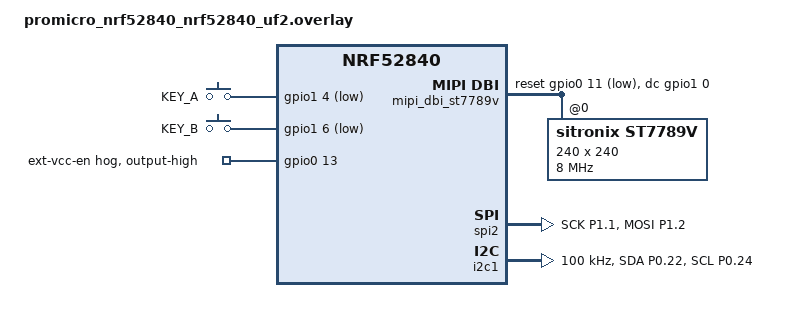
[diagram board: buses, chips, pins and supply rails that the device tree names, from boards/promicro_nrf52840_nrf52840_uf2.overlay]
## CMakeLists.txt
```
cmake_minimum_required(VERSION 3.20.0)
find_package(Zephyr REQUIRED HINTS $ENV{ZEPHYR_BASE})
project(SenseMind_Hardware VERSION 0.7.0 LANGUAGES C)
target_sources(app PRIVATE src/main.c src/sensors.c src/wire.c src/display_ui.c src/buttons.c)
```

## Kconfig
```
mainmenu "SenseMind nRF52840"
source "Kconfig.zephyr"
config SENSEMIND_TEST_DATA
    bool "Generate explicitly marked test samples instead of reading physical sensors"
    default n

config SENSEMIND_BRINGUP_LOG
    bool "Print sensor bring-up diagnostics to the USB console"
    default n

config SENSEMIND_BOOTLOADER_CMD
    bool "Allow the USB console command 'boot' to reboot into the UF2 bootloader"
    default n
```

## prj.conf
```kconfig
# M3 bring-up: BLE peripheral plus the MPU6050 I2C bus. No persistent storage.
CONFIG_BT=y
CONFIG_BT_PERIPHERAL=y
CONFIG_BT_MAX_CONN=1
CONFIG_BT_DEVICE_NAME="SenseMind-Band"
CONFIG_BT_SMP=n
CONFIG_BT_PRIVACY=n
CONFIG_BT_SETTINGS=n
CONFIG_BT_DIS=y
CONFIG_BT_DIS_MODEL_NUMBER=y
CONFIG_BT_DIS_MODEL_NUMBER_STR="SenseMind Band M2"
CONFIG_BT_DIS_MANUF_NAME=y
CONFIG_BT_DIS_MANUF_NAME_STR="SenseMind"
CONFIG_BT_DIS_FW_REV=y
CONFIG_BT_DIS_FW_REV_STR="v0.7.0"
CONFIG_BT_DIS_PNP=n

# LF source is set in the overlay for Zephyr 4.5's split clock driver.
CONFIG_CLOCK_CONTROL_NRF_K32SRC_RC_CALIBRATION=y

# This board's Zephyr definition supplies a USB CDC ACM console.
# It is an application USB stack, separate from the UF2 bootloader's CDC port.
CONFIG_SERIAL=y
CONFIG_CONSOLE=y
CONFIG_UART_CONSOLE=y
CONFIG_PRINTK=y
CONFIG_USB_DEVICE_STACK_NEXT=y
CONFIG_CDC_ACM_SERIAL_INITIALIZE_AT_BOOT=y
CONFIG_CDC_ACM_SERIAL_ENABLE_AT_BOOT=y
CONFIG_CDC_ACM_SERIAL_PRODUCT_STRING="SenseMind Band M2 Console"
CONFIG_CDC_ACM_SERIAL_MANUFACTURER_STRING="SenseMind lab test"
CONFIG_CDC_ACM_SERIAL_MAX_POWER=50

# Keep AP-protection policy consistent with the existing UICR; never lock it.
CONFIG_NRF_APPROTECT_USE_UICR=y

CONFIG_FLASH=n
CONFIG_FLASH_MAP=n
CONFIG_SETTINGS=n
CONFIG_BOOTLOADER_MCUBOOT=n
CONFIG_I2C=y
CONFIG_SPI=y
CONFIG_DISPLAY=y
CONFIG_ST7789V=y
CONFIG_ADC=n
CONFIG_PWM=n
CONFIG_GPIO=y
CONFIG_GPIO_HOGS=y
CONFIG_REBOOT=y
CONFIG_SENSEMIND_BOOTLOADER_CMD=y
CONFIG_WATCHDOG=n
CONFIG_SYSTEM_WORKQUEUE_STACK_SIZE=2048
CONFIG_BUILD_OUTPUT_HEX=y
CONFIG_BUILD_OUTPUT_BIN=y
CONFIG_BUILD_OUTPUT_UF2=y
CONFIG_MINIMAL_LIBC=y
CONFIG_MAIN_STACK_SIZE=8192
# Runtime high-water measurement for the UI thread (debug page).
CONFIG_INIT_STACKS=y
CONFIG_THREAD_STACK_INFO=y
CONFIG_BT_BUF_ACL_RX_SIZE=251
CONFIG_BT_BUF_ACL_TX_SIZE=251
CONFIG_BT_L2CAP_TX_MTU=247
CONFIG_BT_GATT_CLIENT=y
CONFIG_ENTROPY_GENERATOR=y
```

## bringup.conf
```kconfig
# Hardware bring-up build: real sensors plus periodic raw readings on the USB console.
CONFIG_SENSEMIND_TEST_DATA=n
CONFIG_SENSEMIND_BRINGUP_LOG=y
CONFIG_SENSEMIND_BOOTLOADER_CMD=y
```

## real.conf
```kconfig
CONFIG_SENSEMIND_TEST_DATA=n
```

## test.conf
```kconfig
CONFIG_SENSEMIND_TEST_DATA=y
```

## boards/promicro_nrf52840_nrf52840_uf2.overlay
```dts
#include <zephyr/dt-bindings/display/panel.h>
#include <zephyr/dt-bindings/gpio/gpio.h>

/* Adafruit nRF52 UF2 bootloader 0.6.0 accepts app writes below 0xAD000. */
&code_partition {
	reg = <0x00026000 0x00087000>;
};

/* The M2 application has no persistent flash storage. */
/delete-node/ &storage_partition;

/* Do not request any NFC or reset-pin UICR changes at startup. */
&uicr {
	/delete-property/ nfct-pins-as-gpios;
	/delete-property/ gpio-as-nreset;
};

&lfclk {
	k32src = "rc";
	k32src-accuracy-ppm = <500>;
};

/* Radio, native USB, sensor I2C and the ST7789 SPI bus are needed. */
&uart0 { status = "disabled"; };
&adc { status = "disabled"; };
&pwm0 { status = "disabled"; };
&ieee802154 { status = "disabled"; };

/* GPIO1 is used for the display DC/CS lines (P1.00/P1.07). */
&gpio1 { status = "okay"; };

/ {
	leds { status = "disabled"; };
	pwmleds { status = "disabled"; };
};

/*
 * MPU6050 bus on the board's D4/D5 pins: SDA P0.22, SCL P0.24.
 * D2/D3 (P0.17/P0.20) did not respond reliably on this board.
 */
&pinctrl {
	i2c1_sens: i2c1_sens {
		group1 {
			psels = <NRF_PSEL(TWIM_SDA, 0, 22)>,
				<NRF_PSEL(TWIM_SCL, 0, 24)>;
			bias-pull-up;
		};
	};

	i2c1_sens_sleep: i2c1_sens_sleep {
		group1 {
			psels = <NRF_PSEL(TWIM_SDA, 0, 22)>,
				<NRF_PSEL(TWIM_SCL, 0, 24)>;
			low-power-enable;
		};
	};

	/* ST7789: SCK P1.01, MOSI P1.02.  The panel has no MISO. */
	spi2_st7789: spi2_st7789 {
		group1 {
			psels = <NRF_PSEL(SPIM_SCK, 1, 1)>,
				<NRF_PSEL(SPIM_MOSI, 1, 2)>;
		};
	};

	spi2_st7789_sleep: spi2_st7789_sleep {
		group1 {
			psels = <NRF_PSEL(SPIM_SCK, 1, 1)>,
				<NRF_PSEL(SPIM_MOSI, 1, 2)>;
			low-power-enable;
		};
	};
};

&spi2 {
	status = "okay";
	compatible = "nordic,nrf-spim";
	pinctrl-0 = <&spi2_st7789>;
	pinctrl-1 = <&spi2_st7789_sleep>;
	pinctrl-names = "default", "sleep";
	cs-gpios = <&gpio1 7 GPIO_ACTIVE_LOW>;
};

/ {
	chosen {
		zephyr,display = &st7789v;
	};

	buttons {
		compatible = "gpio-keys";

		button_a: button_a {
			gpios = <&gpio1 4 (GPIO_ACTIVE_LOW | GPIO_PULL_UP)>;
			label = "KEY_A";
		};

		button_b: button_b {
			gpios = <&gpio1 6 (GPIO_ACTIVE_LOW | GPIO_PULL_UP)>;
			label = "KEY_B";
		};
	};

	mipi_dbi_st7789v: mipi-dbi-spi {
		compatible = "zephyr,mipi-dbi-spi";
		spi-dev = <&spi2>;
		dc-gpios = <&gpio1 0 GPIO_ACTIVE_HIGH>;
		reset-gpios = <&gpio0 11 GPIO_ACTIVE_LOW>;
		write-only;
		#address-cells = <1>;
		#size-cells = <0>;

		st7789v: st7789v@0 {
			compatible = "sitronix,st7789v";
			reg = <0>;
			mipi-max-frequency = <8000000>;
			width = <240>;
			height = <240>;
			x-offset = <0>;
			y-offset = <0>;
			vcom = <0x19>;
			gctrl = <0x35>;
			vrhs = <0x12>;
			vdvs = <0x20>;
			mdac = <0x00>;
			gamma = <0x01>;
			pixel-format = <PANEL_PIXEL_FORMAT_RGB_565>;
			lcm = <0x2c>;
			porch-param = [0c 0c 00 33 33];
			cmd2en-param = [5a 69 02 01];
			pwctrl1-param = [a4 a1];
			pvgam-param = [d0 04 0d 11 13 2b 3f 54 4c 18 0d 0b 1f 23];
			nvgam-param = [d0 04 0c 11 13 2c 3f 44 51 2f 1f 1f 20 23];
			ram-param = [00 f0];
			rgb-param = [cd 08 14];
			mipi-mode = "MIPI_DBI_MODE_SPI_4WIRE";
		};
	};
};

&i2c0 { status = "disabled"; };

&i2c1 {
	status = "okay";
	compatible = "nordic,nrf-twi";
	clock-frequency = <100000>;
	pinctrl-0 = <&i2c1_sens>;
	pinctrl-1 = <&i2c1_sens_sleep>;
	pinctrl-names = "default", "sleep";
};

/*
 * P0.13 enables the board's 3.3V/VCC output pins (official board doc:
 * driving it low cuts power to them). Keep it high from boot.
 */
&gpio0 {
	status = "okay";
	ext_vcc_en: ext-vcc-en {
		gpio-hog;
		gpios = <13 GPIO_ACTIVE_HIGH>;
		output-high;
		line-name = "ext-vcc-en";
	};
};
```

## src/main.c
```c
/* SenseMind raw telemetry v1. Never flashes, updates UICR, estimates HR, or enables display. */
#include <errno.h>
#include <stdarg.h>
#include <stdio.h>
#include <string.h>
#include <zephyr/kernel.h>
#include <zephyr/bluetooth/bluetooth.h>
#include <zephyr/bluetooth/conn.h>
#include <zephyr/bluetooth/gatt.h>
#include <zephyr/bluetooth/uuid.h>
#include <zephyr/random/random.h>
#include <zephyr/sys/byteorder.h>
#include <zephyr/sys/printk.h>
#include <zephyr/sys/reboot.h>
#include <zephyr/drivers/uart.h>
#include <hal/nrf_ficr.h>
#include <hal/nrf_power.h>
#include "sensors.h"
#include "wire.h"
#include "display_ui.h"
BUILD_ASSERT(DT_REG_ADDR(DT_CHOSEN(zephyr_code_partition))==0x26000,"unsafe UF2 start");
BUILD_ASSERT(DT_REG_SIZE(DT_CHOSEN(zephyr_code_partition))==0x87000,"unsafe UF2 limit");
BUILD_ASSERT(!DT_PROP_OR(DT_NODELABEL(uicr),nfct_pins_as_gpios,0),"UICR NFC write prohibited");
BUILD_ASSERT(!DT_PROP_OR(DT_NODELABEL(uicr),gpio_as_nreset,0),"UICR reset write prohibited");
#define VERSION "v0.7.0"
#define MAX_JSON 4096
#define QUEUE_N 4
#define BATCH_N 64
#define UUID(v) BT_UUID_128_ENCODE(v,0x1d2a,0x4f6e,0x9a7b,0x1c2d3e4f5a60)
static struct bt_uuid_128 service_uuid=BT_UUID_INIT_128(UUID(0x5f9b3c10));
static struct bt_uuid_128 data_uuid=BT_UUID_INIT_128(UUID(0x5f9b3c11));
static struct bt_uuid_128 ack_uuid=BT_UUID_INIT_128(UUID(0x5f9b3c12));
struct message { uint32_t id;uint16_t len,crc;char json[MAX_JSON]; };
static struct message queue[QUEUE_N];static unsigned head,used;
static uint32_t next_id,overruns;static uint16_t fragment;
static int64_t retry_at;
static struct bt_conn *connection;static bool subscribed;
K_MUTEX_DEFINE(lock);
struct batch { int32_t value[6][BATCH_N];unsigned count;uint64_t first_us;int last_error;uint32_t sequence; };
static struct batch imu,ppg;
static char device_id[40],boot_id[40],json_buffer[MAX_JSON];
static void enqueue(const char *json,size_t len) {
 k_mutex_lock(&lock,K_FOREVER);
 if(used==QUEUE_N||len>=MAX_JSON) { overruns++;k_mutex_unlock(&lock);return; }
 struct message *m=&queue[(head+used)%QUEUE_N];m->id=++next_id;m->len=len;
 memcpy(m->json,json,len);m->crc=sm_crc16((const uint8_t *)json,len);used++;
 k_mutex_unlock(&lock);
}
static ssize_t read_data(struct bt_conn *c,const struct bt_gatt_attr *a,void *b,uint16_t len,uint16_t offset) {
 /* READ exposes the transport state, not an ambiguous truncated JSON packet. */
 uint8_t status[8];k_mutex_lock(&lock,K_FOREVER);sys_put_le32(used,status);sys_put_le32(overruns,status+4);k_mutex_unlock(&lock);
 return bt_gatt_attr_read(c,a,b,len,offset,status,sizeof(status));
}
static void ccc(const struct bt_gatt_attr *a,uint16_t value) { ARG_UNUSED(a);subscribed=value==BT_GATT_CCC_NOTIFY;sm_ui_set_ble(connection!=NULL,subscribed); }
static ssize_t write_ack(struct bt_conn *c,const struct bt_gatt_attr *a,const void *buf,uint16_t len,uint16_t offset,uint8_t flags) {
 ARG_UNUSED(c);ARG_UNUSED(a);ARG_UNUSED(flags);const uint8_t *p=buf;
 if(offset||len!=8||p[0]!='S'||p[1]!='A'||p[2]!=1||p[3]>1)return BT_GATT_ERR(BT_ATT_ERR_VALUE_NOT_ALLOWED);
 k_mutex_lock(&lock,K_FOREVER);
 if(used&&sys_get_le32(p+4)==queue[head].id) {
   if(p[3]==0){head=(head+1)%QUEUE_N;used--;}
   fragment=0;retry_at=0;
 }
 k_mutex_unlock(&lock);return len;
}
BT_GATT_SERVICE_DEFINE(sm_service,
 BT_GATT_PRIMARY_SERVICE(&service_uuid),
 BT_GATT_CHARACTERISTIC(&data_uuid.uuid,BT_GATT_CHRC_READ|BT_GATT_CHRC_NOTIFY,BT_GATT_PERM_READ,read_data,NULL,NULL),
 BT_GATT_CCC(ccc,BT_GATT_PERM_READ|BT_GATT_PERM_WRITE),
 BT_GATT_CHARACTERISTIC(&ack_uuid.uuid,BT_GATT_CHRC_WRITE,BT_GATT_PERM_WRITE,NULL,write_ack,NULL));
static const struct bt_data ad[]={BT_DATA_BYTES(BT_DATA_FLAGS,(BT_LE_AD_GENERAL|BT_LE_AD_NO_BREDR)),BT_DATA(BT_DATA_NAME_COMPLETE,CONFIG_BT_DEVICE_NAME,sizeof(CONFIG_BT_DEVICE_NAME)-1)};
static const struct bt_data sd[]={BT_DATA_BYTES(BT_DATA_UUID128_ALL,UUID(0x5f9b3c10))};
static void advertise(struct k_work *work);
K_WORK_DELAYABLE_DEFINE(adv_work,advertise);
static void advertise(struct k_work *work) { ARG_UNUSED(work);int rc=bt_le_adv_start(BT_LE_ADV_CONN_FAST_2,ad,ARRAY_SIZE(ad),sd,ARRAY_SIZE(sd));if(rc&&rc!=-EALREADY){printk("SM ADV retry error=%d\n",rc);k_work_reschedule(&adv_work,K_SECONDS(2));} }
static void mtu_exchanged(struct bt_conn *c,uint8_t error,struct bt_gatt_exchange_params *params) {
 ARG_UNUSED(c);ARG_UNUSED(error);ARG_UNUSED(params);
}
static struct bt_gatt_exchange_params mtu_params={.func=mtu_exchanged};
static void connected(struct bt_conn *c,uint8_t error) {
 if(error){k_work_reschedule(&adv_work,K_SECONDS(1));return;}
 k_mutex_lock(&lock,K_FOREVER);connection=bt_conn_ref(c);fragment=0;retry_at=0;k_mutex_unlock(&lock);
 sm_ui_set_ble(true,false);
 (void)bt_gatt_exchange_mtu(c,&mtu_params);
}
static void disconnected(struct bt_conn *c,uint8_t reason) {
 ARG_UNUSED(c);ARG_UNUSED(reason);k_mutex_lock(&lock,K_FOREVER);
 if(connection){bt_conn_unref(connection);connection=NULL;}subscribed=false;fragment=0;retry_at=0;k_mutex_unlock(&lock);
 sm_ui_set_ble(false,false);
 k_work_reschedule(&adv_work,K_SECONDS(1));
}
BT_CONN_CB_DEFINE(callbacks)={.connected=connected,.disconnected=disconnected};
static void transmit(void) {
 uint8_t frame[244];k_mutex_lock(&lock,K_FOREVER);
 if(!connection||!subscribed||!used){k_mutex_unlock(&lock);return;}
 struct message *m=&queue[head];uint16_t mtu=bt_gatt_get_mtu(connection);
 unsigned payload=MIN(sizeof(frame)-16,(unsigned)(mtu>19?mtu-19:0));
 if(!payload){k_mutex_unlock(&lock);return;}
 unsigned count=DIV_ROUND_UP(m->len,payload);
 if(fragment>=count) {
   if(k_uptime_get()<retry_at){k_mutex_unlock(&lock);return;}
   fragment=0;
 }
 size_t size=sm_fragment((const uint8_t *)m->json,m->len,m->crc,m->id,fragment,payload,frame,sizeof(frame));
 int rc=size?bt_gatt_notify(connection,&sm_service.attrs[2],frame,size):-EINVAL;
 if(!rc){fragment++;if(fragment==count)retry_at=k_uptime_get()+5000;}
 k_mutex_unlock(&lock);
}
static int append(char **p,size_t *left,const char *fmt,...) {
 va_list ap;va_start(ap,fmt);int n=vsnprintf(*p,*left,fmt,ap);va_end(ap);
 if(n<0||(size_t)n>=*left)return -ENOSPC;
 *p+=n;*left-=n;return 0;
}
static void packet(struct batch *b,bool optical) {
 char *p=json_buffer;size_t left=sizeof(json_buffer);bool has=b->count>0;
 const char *names[6]={"ax_raw","ay_raw","az_raw","gx_raw","gy_raw","gz_raw"};
 const char *source=IS_ENABLED(CONFIG_SENSEMIND_TEST_DATA)?"test":"hardware";
 const char *sensor=optical?"max30102":"mpu6050";const char *stream=optical?"ppg":"imu";
 int rc=append(&p,&left,"{\"protocol_version\":\"1.0\",\"device_id\":\"%s\",\"device_type\":\"wearable_nrf52840\",\"source_type\":\"%s\",\"timestamp\":null,\"boot_id\":\"%s\",\"stream_id\":\"%s\",\"sequence_number\":%u,\"sensor_type\":\"%s\",\"sampling_rate\":%s,\"measurements\":{",device_id,source,boot_id,stream,b->sequence++,sensor,has?(optical?"50":"10"):"null");
 for(unsigned ch=0;has&&ch<(optical?2:6)&&!rc;ch++) {
   rc=append(&p,&left,"%s\"%s\":{\"unit\":\"count\",\"samples\":[",ch?",":"",optical?(ch?"ir":"red"):names[ch]);
   for(unsigned i=0;i<b->count&&!rc;i++)rc=append(&p,&left,"%s%d",i?",":"",b->value[ch][i]);
   if(!rc)rc=append(&p,&left,"],\"validity\":[");
   for(unsigned i=0;i<b->count&&!rc;i++)rc=append(&p,&left,"%strue",i?",":"");
   if(!rc)rc=append(&p,&left,"]}");
 }
 bool present=has||b->last_error!=-ENODEV;
 if(!rc)rc=append(&p,&left,"},\"signal_quality\":\"%s\",\"device_status\":{\"connected\":%s,\"sampling\":%s,\"sensor_present\":%s,\"error_codes\":[%s],\"buffer_overruns\":%u,\"heartbeat_interval_seconds\":1,\"firmware_version\":\"%s\"},\"device_time_us\":%llu,\"time_sync\":{\"status\":\"unsynced\"},\"packet_kind\":\"%s\"}",has?"unknown":"invalid",connection?"true":"false",has?"true":"false",present?"true":"false",b->last_error?"\"SENSOR_READ_OR_FIFO_ERROR\"":"",overruns,VERSION,(unsigned long long)(has?b->first_us:k_uptime_get()*1000),has?"samples":"status");
 if(!rc)enqueue(json_buffer,p-json_buffer);else overruns++;
 b->count=0;
}
static void collect(struct batch *b,const int32_t *v,unsigned channels) {
 if(b->count==BATCH_N){overruns++;return;}
 if(!b->count)b->first_us=k_uptime_get()*1000;
 for(unsigned i=0;i<channels;i++){b->value[i][b->count]=v[i];}
 b->count++;
}
#if CONFIG_SENSEMIND_BOOTLOADER_CMD
static void enter_bootloader(void) {
 printk("SM reboot to UF2 bootloader\n");
 k_msleep(20);
 NRF_POWER->GPREGRET=0x57; /* DFU_MAGIC_UF2_RESET: Adafruit/nice!nano UF2 bootloader */
 sys_reboot(SYS_REBOOT_COLD);
}
static void poll_boot_command(void) {
 static char boot_cmd[8];static unsigned boot_len;
 static const struct device *console=DEVICE_DT_GET(DT_CHOSEN(zephyr_console));
 unsigned char c;
 if(!device_is_ready(console))return;
 while(uart_poll_in(console,&c)==0) {
   if(c=='\r'||c=='\n') {
     boot_cmd[boot_len]=0;
     if(!strcmp(boot_cmd,"boot")||!strcmp(boot_cmd,"dfu"))enter_bootloader();
     boot_len=0;
   } else if(boot_len<sizeof(boot_cmd)-1)boot_cmd[boot_len++]=(char)c;
 }
}
#endif
int main(void) {
 snprintf(device_id,sizeof(device_id),"band-%08x%08x",NRF_FICR->DEVICEID[0],NRF_FICR->DEVICEID[1]);
 snprintf(boot_id,sizeof(boot_id),"%08x%08x",sys_rand32_get(),sys_rand32_get());
 sm_ui_set_ids(device_id,boot_id,VERSION);
 if(IS_ENABLED(CONFIG_SENSEMIND_BRINGUP_LOG))printk("SM BOOT %s device=%s\n",VERSION,device_id);
 if(!IS_ENABLED(CONFIG_SENSEMIND_TEST_DATA)) {
   int sensor_rc=sm_sensors_init();
   if(IS_ENABLED(CONFIG_SENSEMIND_BRINGUP_LOG))printk("SM sensors init rc=%d\n",sensor_rc);
 }
 sm_ui_set_sensors(sm_imu_present(),sm_ppg_present());
 int rc=bt_enable(NULL);if(rc){printk("SM BLE unavailable %d\n",rc);return rc;}
 k_work_reschedule(&adv_work,K_NO_WAIT);
 sm_ui_set_ble(false,false);
 int64_t sensor_at=0,imu_at=0,packet_at=1000,log_at=1000,scan_at=2000;
 int32_t last_imu[6]={0};uint32_t last_red=0,last_ir=0;bool have_imu=false,have_ppg=false;
 while(1) {
   int64_t now=k_uptime_get();
   if(now>=sensor_at) {
     sensor_at=now+20;uint32_t red,ir;
     if(IS_ENABLED(CONFIG_SENSEMIND_TEST_DATA)){red=100000+(now%100);ir=120000+(now%100);rc=0;}
     else rc=sm_max30102_read(&red,&ir);
     ppg.last_error=(rc==-EAGAIN)?0:rc;
     if(!rc){
       int32_t v[2]={red,ir};collect(&ppg,v,2);sm_ui_push_ppg(red,ir);
       last_red=red;last_ir=ir;have_ppg=true;
       if(!IS_ENABLED(CONFIG_SENSEMIND_TEST_DATA)) {
         /* Drain bounded backlog so scheduler jitter cannot silently lower FIFO rate. */
         for(unsigned n=1;n<4;n++) {
           int more=sm_max30102_read(&red,&ir);
           if(more){if(more!=-EAGAIN)ppg.last_error=more;break;}
           v[0]=red;v[1]=ir;collect(&ppg,v,2);sm_ui_push_ppg(red,ir);
           last_red=red;last_ir=ir;
         }
       }
     }
     if(ppg.last_error==-EOVERFLOW){overruns++;ppg.count=0;}
   }
   if(now>=imu_at) {
     imu_at=now+100;int16_t raw[6];
     if(IS_ENABLED(CONFIG_SENSEMIND_TEST_DATA)){memset(raw,0,sizeof(raw));raw[2]=16384;rc=0;}else rc=sm_mpu6050_read(raw);
     imu.last_error=rc;
     if(!rc){int32_t v[6];for(unsigned i=0;i<6;i++){v[i]=raw[i];last_imu[i]=raw[i];}collect(&imu,v,6);sm_ui_set_imu(raw);have_imu=true;}
   }
   if(now>=packet_at){
     packet_at=now+1000;packet(&imu,false);packet(&ppg,true);
     sm_ui_set_counters(imu.sequence,overruns);
     sm_ui_set_sensors(imu.last_error==0,ppg.last_error==0);
   }
   if(IS_ENABLED(CONFIG_SENSEMIND_BRINGUP_LOG)&&now>=log_at) {
     log_at=now+1000;
     printk("SM BRINGUP imu_err=%d ppg_err=%d imu=%d ppg=%d",imu.last_error,ppg.last_error,have_imu,have_ppg);
     if(have_imu)printk(" ax=%d ay=%d az=%d gx=%d gy=%d gz=%d",last_imu[0],last_imu[1],last_imu[2],last_imu[3],last_imu[4],last_imu[5]);
     if(have_ppg)printk(" red=%u ir=%u",last_red,last_ir);
     printk("\n");
   }
   if(IS_ENABLED(CONFIG_SENSEMIND_BRINGUP_LOG)&&now>=scan_at&&(!have_imu||!have_ppg)) {
     scan_at=now+5000;
     sm_bringup_scan();
   }
#if CONFIG_SENSEMIND_BOOTLOADER_CMD
   poll_boot_command();
#endif
   transmit();k_msleep(10);
 }
 return 0;
}
```

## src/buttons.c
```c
/*
 * Two physical buttons on the SenseMind H1-02 prototype.
 *
 * KEY_A = P1.04 (board pad 104), KEY_B = P1.06 (board pad 106).
 * Both are wired GPIO -> button -> GND and use the internal pull-up.
 *
 * The GPIO edge interrupt only wakes the button thread.  Debounce, short/long
 * classification and event queuing happen in that thread, never in the ISR.
 */
#include <errno.h>
#include <stdbool.h>
#include <stdint.h>

#include <zephyr/device.h>
#include <zephyr/drivers/gpio.h>
#include <zephyr/kernel.h>
#include <zephyr/sys/atomic.h>
#include <zephyr/sys/printk.h>

#include "buttons.h"

#define DEBOUNCE_MS 30
#define SHORT_MIN_MS 40
#define SHORT_MAX_MS 600
#define LONG_MS 800

static const struct gpio_dt_spec button_spec[2] = {
	[BTN_A] = GPIO_DT_SPEC_GET(DT_NODELABEL(button_a), gpios),
	[BTN_B] = GPIO_DT_SPEC_GET(DT_NODELABEL(button_b), gpios),
};

struct button_state {
	bool raw_last;
	bool stable;
	int64_t change_at;
	int64_t press_at;
	bool long_sent;
};

static struct button_state state[2];
static struct k_sem button_sem;
static struct gpio_callback button_cb;
static atomic_t dropped_events;

K_MSGQ_DEFINE(button_msgq, sizeof(struct button_event), 8, 4);

static void button_isr(const struct device *port, struct gpio_callback *cb,
		       uint32_t pins)
{
	ARG_UNUSED(port);
	ARG_UNUSED(cb);
	ARG_UNUSED(pins);

	k_sem_give(&button_sem);
}

static void post_event(enum button_id id, enum button_event_type type)
{
	struct button_event ev = {
		.id = (uint8_t)id,
		.type = (uint8_t)type,
	};

	if (k_msgq_put(&button_msgq, &ev, K_NO_WAIT) != 0) {
		atomic_inc(&dropped_events);
	}

#if IS_ENABLED(CONFIG_SENSEMIND_BRINGUP_LOG)
	printk("SM BTN %c %s\n", id == BTN_A ? 'A' : 'B',
	       type == BTN_SHORT ? "SHORT" : "LONG");
#endif
}

static int buttons_init(void)
{
	k_sem_init(&button_sem, 0, 1);

	for (int i = 0; i < 2; i++) {
		if (!gpio_is_ready_dt(&button_spec[i])) {
			printk("SM BTN %c GPIO not ready\n", i == BTN_A ? 'A' : 'B');
			return -ENODEV;
		}

		int rc = gpio_pin_configure_dt(&button_spec[i], GPIO_INPUT);

		if (rc != 0) {
			printk("SM BTN %c configure rc=%d\n", i == BTN_A ? 'A' : 'B', rc);
			return rc;
		}

		rc = gpio_pin_interrupt_configure_dt(&button_spec[i],
						     GPIO_INT_EDGE_BOTH);
		if (rc != 0) {
			/* Polling fallback: the thread still samples every 10 ms. */
			printk("SM BTN %c irq rc=%d (poll fallback)\n",
			       i == BTN_A ? 'A' : 'B', rc);
		}
	}

	/* Both buttons are on GPIO1 on this board. */
	if (button_spec[BTN_A].port != button_spec[BTN_B].port) {
		printk("SM BTN ports differ; irq grouping disabled\n");
		return 0;
	}

	gpio_init_callback(&button_cb, button_isr,
			   BIT(button_spec[BTN_A].pin) |
			   BIT(button_spec[BTN_B].pin));
	int rc = gpio_add_callback(button_spec[BTN_A].port, &button_cb);

	if (rc != 0) {
		printk("SM BTN callback rc=%d (poll fallback)\n", rc);
	}

	for (int i = 0; i < 2; i++) {
		state[i].raw_last = gpio_pin_get_dt(&button_spec[i]) != 0;
		state[i].stable = state[i].raw_last;
		state[i].change_at = k_uptime_get();
		state[i].press_at = state[i].change_at;
		state[i].long_sent = false;
	}

#if IS_ENABLED(CONFIG_SENSEMIND_BRINGUP_LOG)
	printk("SM BTN ready A=P1.04 B=P1.06\n");
#endif

	return 0;
}

static void button_thread(void *a, void *b, void *c)
{
	ARG_UNUSED(a);
	ARG_UNUSED(b);
	ARG_UNUSED(c);

	if (buttons_init() != 0) {
		printk("SM BTN init failed\n");
		return;
	}

	while (1) {
		/* A 10 ms timeout also provides the polling fallback if the
		 * GPIO interrupt is unavailable. */
		(void)k_sem_take(&button_sem, K_MSEC(10));

		int64_t now = k_uptime_get();

		for (int i = 0; i < 2; i++) {
			bool raw = gpio_pin_get_dt(&button_spec[i]) != 0;
			struct button_state *st = &state[i];

			if (raw != st->raw_last) {
				st->raw_last = raw;
				st->change_at = now;
			}

			if (now - st->change_at >= DEBOUNCE_MS &&
			    st->stable != st->raw_last) {
				st->stable = st->raw_last;

				if (st->stable) {
					st->press_at = now;
					st->long_sent = false;
				} else {
					int64_t held = now - st->press_at;

					if (!st->long_sent &&
					    held >= SHORT_MIN_MS &&
					    held <= SHORT_MAX_MS) {
						post_event((enum button_id)i,
							   BTN_SHORT);
					}
				}
			}

			if (st->stable && !st->long_sent &&
			    now - st->press_at >= LONG_MS) {
				post_event((enum button_id)i, BTN_LONG);
				st->long_sent = true;
			}
		}
	}
}

K_THREAD_DEFINE(sm_button_thread_id, 2048, button_thread,
		NULL, NULL, NULL, 6, 0, 0);

int buttons_get_event(struct button_event *ev, k_timeout_t timeout)
{
	return k_msgq_get(&button_msgq, ev, timeout);
}

uint32_t buttons_dropped_events(void)
{
	return (uint32_t)atomic_get(&dropped_events);
}
```

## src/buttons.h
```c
#ifndef SENSEMIND_BUTTONS_H
#define SENSEMIND_BUTTONS_H

#include <stdint.h>
#include <zephyr/kernel.h>

enum button_id {
	BTN_A = 0,
	BTN_B = 1,
};

enum button_event_type {
	BTN_SHORT = 0,
	BTN_LONG = 1,
};

struct button_event {
	uint8_t id;
	uint8_t type;
};

/* Wait for a debounced short/long event.  Returns 0 on success, -EAGAIN on
 * timeout, or another negative errno. */
int buttons_get_event(struct button_event *ev, k_timeout_t timeout);

/* Number of events dropped because the queue was full (diagnostics). */
uint32_t buttons_dropped_events(void);

#endif /* SENSEMIND_BUTTONS_H */
```

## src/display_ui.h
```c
#ifndef SENSEMIND_DISPLAY_UI_H
#define SENSEMIND_DISPLAY_UI_H

#include <stdbool.h>
#include <stdint.h>

/* Called from the H1 main loop / BLE callbacks.  All functions are safe to
 * call from any thread; they only update a small shared snapshot. */
void sm_ui_set_ble(bool connected, bool subscribed);
void sm_ui_set_sensors(bool imu_ok, bool ppg_ok);
void sm_ui_set_imu(const int16_t raw[6]);
void sm_ui_push_ppg(uint32_t red, uint32_t ir);
void sm_ui_set_counters(uint32_t seq, uint32_t overruns);
void sm_ui_set_ids(const char *device_id, const char *boot_id, const char *fw);

#endif /* SENSEMIND_DISPLAY_UI_H */
```

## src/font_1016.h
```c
/* DroidSansMono 10x16 font data, from Zephyr subsys/fb/cfb_fonts.c.
 * Copyright (C) 2008 The Android Open Source Project, Apache-2.0.
 * Column-major, two bytes per column, bit 0 = top row. */
#ifndef SM_FONT_1016_H
#define SM_FONT_1016_H
#include <stdint.h>
static const uint8_t sm_font_1016[95][20] = {
    { 0x00, 0x00, 0x00, 0x00, 0x00, 0x00, 0x00, 0x00, 0x00, 0x00, 0x00, 0x00, 0x00, 0x00, 0x00, 0x00, 0x00, 0x00, 0x00, 0x00 },
    { 0x00, 0x00, 0x00, 0x00, 0x00, 0x00, 0x00, 0x00, 0x00, 0x00, 0xf8, 0x1b, 0x38, 0x18, 0x00, 0x00, 0x00, 0x00, 0x00, 0x00 },
    { 0x00, 0x00, 0x00, 0x00, 0x00, 0x00, 0x00, 0x00, 0x38, 0x00, 0x08, 0x00, 0x00, 0x00, 0x38, 0x00, 0x08, 0x00, 0x00, 0x00 },
    { 0x00, 0x00, 0x00, 0x02, 0x40, 0x1e, 0xe0, 0x07, 0x78, 0x02, 0x40, 0x1e, 0xe0, 0x07, 0x78, 0x02, 0x40, 0x00, 0x00, 0x00 },
    { 0x00, 0x00, 0x00, 0x00, 0x00, 0x00, 0x70, 0x10, 0x88, 0x10, 0xfe, 0x7f, 0x08, 0x11, 0x08, 0x0e, 0x00, 0x00, 0x00, 0x00 },
    { 0x00, 0x00, 0x70, 0x00, 0x88, 0x10, 0x88, 0x0c, 0x70, 0x03, 0xc0, 0x0e, 0x30, 0x11, 0x08, 0x11, 0x00, 0x0e, 0x00, 0x00 },
    { 0x00, 0x00, 0x00, 0x00, 0x00, 0x0e, 0x70, 0x19, 0x88, 0x10, 0xc8, 0x13, 0x70, 0x0c, 0x00, 0x1f, 0x00, 0x10, 0x00, 0x00 },
    { 0x00, 0x00, 0x00, 0x00, 0x00, 0x00, 0x00, 0x00, 0x00, 0x00, 0x38, 0x00, 0x08, 0x00, 0x00, 0x00, 0x00, 0x00, 0x00, 0x00 },
    { 0x00, 0x00, 0x00, 0x00, 0x00, 0x00, 0x00, 0x00, 0xc0, 0x0f, 0x70, 0x38, 0x18, 0x60, 0x00, 0x00, 0x00, 0x00, 0x00, 0x00 },
    { 0x00, 0x00, 0x00, 0x00, 0x00, 0x00, 0x00, 0x00, 0x00, 0x00, 0x18, 0x60, 0x70, 0x38, 0xc0, 0x0f, 0x00, 0x00, 0x00, 0x00 },
    { 0x00, 0x00, 0x00, 0x00, 0x00, 0x00, 0x10, 0x00, 0x90, 0x00, 0xd0, 0x00, 0x3c, 0x00, 0xd0, 0x00, 0x90, 0x00, 0x10, 0x00 },
    { 0x00, 0x00, 0x00, 0x00, 0x00, 0x00, 0x00, 0x01, 0x00, 0x01, 0x00, 0x01, 0xe0, 0x0f, 0x00, 0x01, 0x00, 0x01, 0x00, 0x01 },
    { 0x00, 0x00, 0x00, 0x00, 0x00, 0x00, 0x00, 0x00, 0x00, 0x00, 0x00, 0x38, 0x00, 0x18, 0x00, 0x00, 0x00, 0x00, 0x00, 0x00 },
    { 0x00, 0x00, 0x00, 0x00, 0x00, 0x00, 0x00, 0x00, 0x00, 0x02, 0x00, 0x02, 0x00, 0x02, 0x00, 0x02, 0x00, 0x00, 0x00, 0x00 },
    { 0x00, 0x00, 0x00, 0x00, 0x00, 0x00, 0x00, 0x00, 0x00, 0x00, 0x00, 0x18, 0x00, 0x18, 0x00, 0x00, 0x00, 0x00, 0x00, 0x00 },
    { 0x00, 0x00, 0x00, 0x00, 0x00, 0x00, 0x00, 0x10, 0x00, 0x0c, 0x00, 0x03, 0xc0, 0x00, 0x30, 0x00, 0x08, 0x00, 0x00, 0x00 },
    { 0x00, 0x00, 0x00, 0x00, 0x00, 0x00, 0xe0, 0x07, 0x38, 0x1c, 0x08, 0x10, 0x08, 0x10, 0x38, 0x1c, 0xe0, 0x07, 0x00, 0x00 },
    { 0x00, 0x00, 0x00, 0x00, 0x00, 0x00, 0x00, 0x00, 0x20, 0x00, 0x10, 0x00, 0xf8, 0x1f, 0x00, 0x00, 0x00, 0x00, 0x00, 0x00 },
    { 0x00, 0x00, 0x00, 0x00, 0x00, 0x00, 0x10, 0x10, 0x08, 0x1c, 0x08, 0x16, 0x08, 0x13, 0x98, 0x11, 0x70, 0x10, 0x00, 0x00 },
    { 0x00, 0x00, 0x00, 0x00, 0x00, 0x00, 0x10, 0x10, 0x08, 0x10, 0x88, 0x10, 0x88, 0x10, 0x58, 0x19, 0x70, 0x0f, 0x00, 0x00 },
    { 0x00, 0x00, 0x00, 0x00, 0x00, 0x00, 0x00, 0x06, 0x80, 0x05, 0x60, 0x04, 0x10, 0x04, 0xf8, 0x1f, 0x00, 0x04, 0x00, 0x00 },
    { 0x00, 0x00, 0x00, 0x00, 0x00, 0x00, 0xf8, 0x10, 0x88, 0x10, 0x88, 0x10, 0x88, 0x10, 0x88, 0x19, 0x08, 0x0f, 0x00, 0x00 },
    { 0x00, 0x00, 0x00, 0x00, 0x00, 0x00, 0xc0, 0x07, 0x70, 0x19, 0x98, 0x10, 0x88, 0x10, 0x88, 0x19, 0x08, 0x0f, 0x00, 0x00 },
    { 0x00, 0x00, 0x00, 0x00, 0x00, 0x00, 0x08, 0x00, 0x08, 0x10, 0x08, 0x0e, 0x88, 0x03, 0x68, 0x00, 0x18, 0x00, 0x00, 0x00 },
    { 0x00, 0x00, 0x00, 0x00, 0x00, 0x00, 0x70, 0x0e, 0xd8, 0x19, 0x88, 0x10, 0x88, 0x10, 0x58, 0x19, 0x70, 0x0e, 0x00, 0x00 },
    { 0x00, 0x00, 0x00, 0x00, 0x00, 0x00, 0xf0, 0x10, 0x98, 0x11, 0x08, 0x11, 0x08, 0x19, 0x98, 0x0e, 0xe0, 0x03, 0x00, 0x00 },
    { 0x00, 0x00, 0x00, 0x00, 0x00, 0x00, 0x00, 0x00, 0x00, 0x00, 0x60, 0x18, 0x60, 0x18, 0x00, 0x00, 0x00, 0x00, 0x00, 0x00 },
    { 0x00, 0x00, 0x00, 0x00, 0x00, 0x00, 0x00, 0x00, 0x00, 0x00, 0x60, 0x38, 0x60, 0x18, 0x00, 0x00, 0x00, 0x00, 0x00, 0x00 },
    { 0x00, 0x00, 0x00, 0x00, 0x00, 0x00, 0x00, 0x01, 0x80, 0x02, 0x80, 0x02, 0x40, 0x04, 0x40, 0x04, 0x20, 0x08, 0x00, 0x00 },
    { 0x00, 0x00, 0x00, 0x00, 0x00, 0x00, 0x80, 0x02, 0x80, 0x02, 0x80, 0x02, 0x80, 0x02, 0x80, 0x02, 0x80, 0x02, 0x00, 0x00 },
    { 0x00, 0x00, 0x00, 0x00, 0x00, 0x00, 0x20, 0x08, 0x40, 0x04, 0x40, 0x04, 0x80, 0x02, 0x80, 0x02, 0x00, 0x01, 0x00, 0x00 },
    { 0x00, 0x00, 0x00, 0x00, 0x00, 0x00, 0x18, 0x00, 0x08, 0x00, 0x08, 0x1a, 0x88, 0x19, 0xd8, 0x00, 0x70, 0x00, 0x00, 0x00 },
    { 0x00, 0x00, 0xc0, 0x0f, 0x30, 0x18, 0x88, 0x23, 0x48, 0x24, 0x48, 0x24, 0xc8, 0x23, 0x10, 0x24, 0xe0, 0x03, 0x00, 0x00 },
    { 0x00, 0x00, 0x00, 0x10, 0x00, 0x0e, 0xc0, 0x03, 0x38, 0x02, 0x38, 0x02, 0xc0, 0x03, 0x00, 0x0e, 0x00, 0x10, 0x00, 0x00 },
    { 0x00, 0x00, 0x00, 0x00, 0x00, 0x00, 0xf8, 0x1f, 0x88, 0x10, 0x88, 0x10, 0x88, 0x10, 0x58, 0x19, 0x70, 0x0f, 0x00, 0x00 },
    { 0x00, 0x00, 0x00, 0x00, 0xe0, 0x07, 0x30, 0x0c, 0x18, 0x18, 0x08, 0x10, 0x08, 0x10, 0x18, 0x10, 0x00, 0x00, 0x00, 0x00 },
    { 0x00, 0x00, 0x00, 0x00, 0x00, 0x00, 0xf8, 0x1f, 0x08, 0x10, 0x08, 0x10, 0x18, 0x18, 0x30, 0x0c, 0xe0, 0x07, 0x00, 0x00 },
    { 0x00, 0x00, 0x00, 0x00, 0x00, 0x00, 0xf8, 0x1f, 0x88, 0x10, 0x88, 0x10, 0x88, 0x10, 0x88, 0x10, 0x88, 0x10, 0x00, 0x00 },
    { 0x00, 0x00, 0x00, 0x00, 0x00, 0x00, 0xf8, 0x1f, 0x88, 0x00, 0x88, 0x00, 0x88, 0x00, 0x88, 0x00, 0x88, 0x00, 0x00, 0x00 },
    { 0x00, 0x00, 0x00, 0x00, 0x00, 0x00, 0xe0, 0x07, 0x30, 0x0c, 0x18, 0x10, 0x88, 0x10, 0x88, 0x10, 0x88, 0x1f, 0x00, 0x00 },
    { 0x00, 0x00, 0x00, 0x00, 0x00, 0x00, 0xf8, 0x1f, 0x80, 0x00, 0x80, 0x00, 0x80, 0x00, 0x80, 0x00, 0xf8, 0x1f, 0x00, 0x00 },
    { 0x00, 0x00, 0x00, 0x00, 0x00, 0x00, 0x08, 0x10, 0x08, 0x10, 0xf8, 0x1f, 0x08, 0x10, 0x08, 0x10, 0x00, 0x00, 0x00, 0x00 },
    { 0x00, 0x00, 0x00, 0x00, 0x00, 0x00, 0x00, 0x10, 0x00, 0x10, 0x00, 0x10, 0x00, 0x18, 0xf8, 0x0f, 0x00, 0x00, 0x00, 0x00 },
    { 0x00, 0x00, 0x00, 0x00, 0xf8, 0x1f, 0x00, 0x01, 0x80, 0x00, 0x40, 0x03, 0x30, 0x06, 0x18, 0x18, 0x08, 0x10, 0x00, 0x00 },
    { 0x00, 0x00, 0x00, 0x00, 0x00, 0x00, 0xf8, 0x1f, 0x00, 0x10, 0x00, 0x10, 0x00, 0x10, 0x00, 0x10, 0x00, 0x10, 0x00, 0x00 },
    { 0x00, 0x00, 0x00, 0x00, 0xf8, 0x1f, 0x70, 0x00, 0x80, 0x07, 0x00, 0x1c, 0x80, 0x03, 0x70, 0x00, 0xf8, 0x1f, 0x00, 0x00 },
    { 0x00, 0x00, 0x00, 0x00, 0x00, 0x00, 0xf8, 0x1f, 0x30, 0x00, 0xc0, 0x00, 0x00, 0x03, 0x00, 0x0c, 0xf8, 0x1f, 0x00, 0x00 },
    { 0x00, 0x00, 0x00, 0x00, 0x00, 0x00, 0xe0, 0x07, 0x38, 0x1c, 0x08, 0x10, 0x08, 0x10, 0x38, 0x1c, 0xe0, 0x07, 0x00, 0x00 },
    { 0x00, 0x00, 0x00, 0x00, 0x00, 0x00, 0xf8, 0x1f, 0x08, 0x01, 0x08, 0x01, 0x08, 0x01, 0x98, 0x01, 0xf0, 0x00, 0x00, 0x00 },
    { 0x00, 0x00, 0x00, 0x00, 0x00, 0x00, 0xe0, 0x07, 0x38, 0x1c, 0x08, 0x10, 0x08, 0x10, 0x38, 0x6c, 0xe0, 0xc7, 0x00, 0x00 },
    { 0x00, 0x00, 0x00, 0x00, 0x00, 0x00, 0xf8, 0x1f, 0x08, 0x01, 0x08, 0x01, 0x08, 0x03, 0x98, 0x07, 0xf0, 0x18, 0x00, 0x10 },
    { 0x00, 0x00, 0x00, 0x00, 0x00, 0x00, 0x70, 0x10, 0xd8, 0x10, 0x88, 0x10, 0x88, 0x11, 0x08, 0x19, 0x18, 0x0e, 0x00, 0x00 },
    { 0x00, 0x00, 0x00, 0x00, 0x08, 0x00, 0x08, 0x00, 0x08, 0x00, 0xf8, 0x1f, 0x08, 0x00, 0x08, 0x00, 0x08, 0x00, 0x00, 0x00 },
    { 0x00, 0x00, 0x00, 0x00, 0x00, 0x00, 0xf8, 0x0f, 0x00, 0x18, 0x00, 0x10, 0x00, 0x10, 0x00, 0x18, 0xf8, 0x0f, 0x00, 0x00 },
    { 0x00, 0x00, 0x08, 0x00, 0x70, 0x00, 0x80, 0x03, 0x00, 0x1c, 0x00, 0x1c, 0x80, 0x03, 0x70, 0x00, 0x08, 0x00, 0x00, 0x00 },
    { 0x00, 0x00, 0x78, 0x00, 0xc0, 0x1f, 0x00, 0x0e, 0xc0, 0x01, 0x80, 0x01, 0x00, 0x06, 0x80, 0x1f, 0x78, 0x00, 0x00, 0x00 },
    { 0x00, 0x00, 0x08, 0x10, 0x18, 0x08, 0x60, 0x06, 0xc0, 0x01, 0xc0, 0x03, 0x60, 0x06, 0x18, 0x18, 0x08, 0x10, 0x00, 0x00 },
    { 0x00, 0x00, 0x08, 0x00, 0x38, 0x00, 0xe0, 0x00, 0x00, 0x1f, 0xc0, 0x00, 0x30, 0x00, 0x08, 0x00, 0x00, 0x00, 0x00, 0x00 },
    { 0x00, 0x00, 0x00, 0x00, 0x00, 0x00, 0x08, 0x18, 0x08, 0x1e, 0x08, 0x13, 0xc8, 0x10, 0x78, 0x10, 0x18, 0x10, 0x00, 0x00 },
    { 0x00, 0x00, 0x00, 0x00, 0x00, 0x00, 0x00, 0x00, 0x00, 0x00, 0xf8, 0x7f, 0x08, 0x40, 0x08, 0x40, 0x00, 0x00, 0x00, 0x00 },
    { 0x00, 0x00, 0x00, 0x00, 0x00, 0x00, 0x08, 0x00, 0x30, 0x00, 0xc0, 0x00, 0x00, 0x03, 0x00, 0x0c, 0x00, 0x10, 0x00, 0x00 },
    { 0x00, 0x00, 0x00, 0x00, 0x00, 0x00, 0x00, 0x00, 0x08, 0x40, 0x08, 0x40, 0xf8, 0x7f, 0x00, 0x00, 0x00, 0x00, 0x00, 0x00 },
    { 0x00, 0x00, 0x00, 0x00, 0x00, 0x00, 0x00, 0x01, 0xc0, 0x00, 0x38, 0x00, 0x38, 0x00, 0xc0, 0x00, 0x00, 0x01, 0x00, 0x00 },
    { 0x00, 0x40, 0x00, 0x40, 0x00, 0x40, 0x00, 0x40, 0x00, 0x40, 0x00, 0x40, 0x00, 0x40, 0x00, 0x40, 0x00, 0x00, 0x00, 0x00 },
    { 0x00, 0x00, 0x00, 0x00, 0x00, 0x00, 0x00, 0x00, 0x04, 0x00, 0x0c, 0x00, 0x08, 0x00, 0x00, 0x00, 0x00, 0x00, 0x00, 0x00 },
    { 0x00, 0x00, 0x00, 0x00, 0x00, 0x00, 0x00, 0x0e, 0x20, 0x13, 0x20, 0x11, 0x20, 0x11, 0x60, 0x09, 0xc0, 0x1f, 0x00, 0x00 },
    { 0x00, 0x00, 0x00, 0x00, 0x00, 0x00, 0xfc, 0x1f, 0x40, 0x08, 0x20, 0x10, 0x20, 0x10, 0x60, 0x18, 0xc0, 0x0f, 0x00, 0x00 },
    { 0x00, 0x00, 0x00, 0x00, 0x00, 0x00, 0x80, 0x07, 0xc0, 0x08, 0x20, 0x10, 0x20, 0x10, 0x20, 0x10, 0x20, 0x10, 0x00, 0x00 },
    { 0x00, 0x00, 0x00, 0x00, 0x00, 0x00, 0xc0, 0x0f, 0x60, 0x18, 0x20, 0x10, 0x20, 0x10, 0x40, 0x08, 0xfc, 0x1f, 0x00, 0x00 },
    { 0x00, 0x00, 0x00, 0x00, 0x00, 0x00, 0x80, 0x07, 0x60, 0x09, 0x20, 0x11, 0x20, 0x11, 0x60, 0x11, 0xc0, 0x19, 0x00, 0x00 },
    { 0x00, 0x00, 0x00, 0x00, 0x00, 0x00, 0x20, 0x00, 0x20, 0x00, 0xf8, 0x1f, 0x24, 0x00, 0x24, 0x00, 0x24, 0x00, 0x00, 0x00 },
    { 0x00, 0x00, 0x00, 0x00, 0x00, 0x00, 0xc0, 0x7d, 0x20, 0x9a, 0x20, 0x8a, 0x20, 0x8a, 0x20, 0x8a, 0xe0, 0xc9, 0x20, 0x70 },
    { 0x00, 0x00, 0x00, 0x00, 0x00, 0x00, 0xfc, 0x1f, 0x40, 0x00, 0x20, 0x00, 0x20, 0x00, 0x60, 0x00, 0xc0, 0x1f, 0x00, 0x00 },
    { 0x00, 0x00, 0x00, 0x00, 0x00, 0x00, 0x00, 0x10, 0x20, 0x10, 0x20, 0x10, 0xec, 0x1f, 0x00, 0x10, 0x00, 0x10, 0x00, 0x00 },
    { 0x00, 0x00, 0x00, 0x00, 0x00, 0x00, 0x00, 0x80, 0x20, 0x80, 0x20, 0x80, 0x20, 0xc0, 0xec, 0x7f, 0x00, 0x00, 0x00, 0x00 },
    { 0x00, 0x00, 0x00, 0x00, 0x00, 0x00, 0xfc, 0x1f, 0x00, 0x02, 0x00, 0x03, 0x80, 0x06, 0x40, 0x0c, 0x20, 0x18, 0x00, 0x10 },
    { 0x00, 0x00, 0x00, 0x00, 0x00, 0x00, 0x00, 0x10, 0x04, 0x10, 0x04, 0x10, 0xfc, 0x1f, 0x00, 0x10, 0x00, 0x10, 0x00, 0x00 },
    { 0x00, 0x00, 0x00, 0x00, 0xe0, 0x1f, 0x40, 0x00, 0x20, 0x00, 0xc0, 0x1f, 0x20, 0x00, 0x20, 0x00, 0xc0, 0x1f, 0x00, 0x00 },
    { 0x00, 0x00, 0x00, 0x00, 0x00, 0x00, 0xe0, 0x1f, 0x40, 0x00, 0x20, 0x00, 0x20, 0x00, 0x60, 0x00, 0xc0, 0x1f, 0x00, 0x00 },
    { 0x00, 0x00, 0x00, 0x00, 0x00, 0x00, 0x80, 0x07, 0x60, 0x18, 0x20, 0x10, 0x20, 0x10, 0x60, 0x18, 0x80, 0x07, 0x00, 0x00 },
    { 0x00, 0x00, 0x00, 0x00, 0x00, 0x00, 0xe0, 0xff, 0x40, 0x08, 0x20, 0x10, 0x20, 0x10, 0x60, 0x18, 0xc0, 0x0f, 0x00, 0x00 },
    { 0x00, 0x00, 0x00, 0x00, 0x00, 0x00, 0xc0, 0x0f, 0x60, 0x18, 0x20, 0x10, 0x20, 0x10, 0x40, 0x08, 0xe0, 0xff, 0x00, 0x00 },
    { 0x00, 0x00, 0x00, 0x00, 0x00, 0x00, 0x00, 0x00, 0xe0, 0x1f, 0x40, 0x00, 0x20, 0x00, 0x20, 0x00, 0x20, 0x00, 0x00, 0x00 },
    { 0x00, 0x00, 0x00, 0x00, 0x00, 0x00, 0xc0, 0x10, 0x20, 0x11, 0x20, 0x11, 0x20, 0x13, 0x20, 0x12, 0x60, 0x0e, 0x00, 0x00 },
    { 0x00, 0x00, 0x00, 0x00, 0x00, 0x00, 0x10, 0x00, 0x10, 0x00, 0xfc, 0x07, 0x10, 0x08, 0x10, 0x08, 0x10, 0x08, 0x00, 0x00 },
    { 0x00, 0x00, 0x00, 0x00, 0x00, 0x00, 0xe0, 0x0f, 0x00, 0x18, 0x00, 0x10, 0x00, 0x10, 0x00, 0x08, 0xe0, 0x1f, 0x00, 0x00 },
    { 0x00, 0x00, 0x00, 0x00, 0x00, 0x00, 0x60, 0x00, 0xc0, 0x03, 0x00, 0x1c, 0x00, 0x1c, 0xc0, 0x03, 0x60, 0x00, 0x00, 0x00 },
    { 0xe0, 0x03, 0x00, 0x1c, 0x00, 0x07, 0xe0, 0x00, 0xe0, 0x00, 0x00, 0x0f, 0x00, 0x1c, 0xe0, 0x03, 0x00, 0x00, 0x00, 0x00 },
    { 0x00, 0x00, 0x00, 0x00, 0x00, 0x00, 0x20, 0x10, 0x60, 0x0c, 0x80, 0x07, 0x80, 0x07, 0x60, 0x0c, 0x20, 0x10, 0x00, 0x00 },
    { 0x00, 0x00, 0x00, 0x00, 0x00, 0x00, 0x60, 0x80, 0xc0, 0x83, 0x00, 0x7c, 0x00, 0x1c, 0xc0, 0x03, 0x60, 0x00, 0x00, 0x00 },
    { 0x00, 0x00, 0x00, 0x00, 0x00, 0x00, 0x20, 0x18, 0x20, 0x1c, 0x20, 0x16, 0x20, 0x11, 0xe0, 0x10, 0x60, 0x10, 0x00, 0x00 },
    { 0x00, 0x00, 0x00, 0x00, 0x00, 0x00, 0x00, 0x00, 0x00, 0x01, 0x00, 0x01, 0xf0, 0x3e, 0x08, 0x40, 0x08, 0x40, 0x00, 0x00 },
    { 0x00, 0x00, 0x00, 0x00, 0x00, 0x00, 0x00, 0x00, 0x00, 0x00, 0x00, 0x00, 0xfc, 0xff, 0x00, 0x00, 0x00, 0x00, 0x00, 0x00 },
    { 0x00, 0x00, 0x00, 0x00, 0x00, 0x00, 0x08, 0x40, 0x08, 0x40, 0xf0, 0x3e, 0x00, 0x01, 0x00, 0x01, 0x00, 0x00, 0x00, 0x00 },
    { 0x00, 0x00, 0x00, 0x00, 0x00, 0x00, 0x80, 0x00, 0x80, 0x00, 0x80, 0x00, 0x00, 0x01, 0x00, 0x01, 0x00, 0x01, 0x00, 0x00 },
};
#endif
```

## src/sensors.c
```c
/* Raw register interfaces only: no invented HR or medical quality. */
#include "sensors.h"
#include <errno.h>
#include <zephyr/device.h>
#include <zephyr/devicetree.h>
#include <zephyr/drivers/i2c.h>
#include <zephyr/kernel.h>
#include <zephyr/sys/byteorder.h>
#include <zephyr/sys/printk.h>
static const struct device *bus;
static bool imu_ok,ppg_ok;
bool sm_imu_present(void) { return imu_ok; }
bool sm_ppg_present(void) { return ppg_ok; }
int sm_sensors_init(void) {
 bus=DEVICE_DT_GET(DT_NODELABEL(i2c1));
 if(!device_is_ready(bus)) {
   if(IS_ENABLED(CONFIG_SENSEMIND_BRINGUP_LOG))printk("SM I2C1 not ready\n");
   return -ENODEV;
 }
 if(IS_ENABLED(CONFIG_SENSEMIND_BRINGUP_LOG)) {
   printk("SM I2C scan:");
   for(uint8_t a=0x08;a<0x78;a++){uint8_t v;if(!i2c_reg_read_byte(bus,a,0x00,&v))printk(" 0x%02x",a);}
   printk("\n");
 }
 uint8_t id=0;
 int rc_imu_id=i2c_reg_read_byte(bus,0x68,0x75,&id);
 /* MPU6050/6000 report 0x68; many MPU6500/9250 clones report 0x70/0x71. */
 bool imu_id_ok=(id==0x68||id==0x69||id==0x70||id==0x71);
 if(!rc_imu_id && imu_id_ok &&
    !i2c_reg_write_byte(bus,0x68,0x6b,0x00) &&
    !i2c_reg_write_byte(bus,0x68,0x1b,0x00) && !i2c_reg_write_byte(bus,0x68,0x1c,0x00))imu_ok=true;
 if(IS_ENABLED(CONFIG_SENSEMIND_BRINGUP_LOG))
   printk("SM MPU6050 who_am_i rc=%d id=0x%02x ready=%d\n",rc_imu_id,id,imu_ok);
 /* MAX30102: verify PART_ID, reset, FIFO and 50 Hz red+IR acquisition. */
 int rc_ppg_id=i2c_reg_read_byte(bus,0x57,0xff,&id);
 if(!rc_ppg_id && id==0x15) {
   if(!i2c_reg_write_byte(bus,0x57,0x09,0x40)) {
     k_msleep(20);
     ppg_ok=!i2c_reg_write_byte(bus,0x57,0x04,0) && !i2c_reg_write_byte(bus,0x57,0x05,0) &&
       !i2c_reg_write_byte(bus,0x57,0x06,0) && !i2c_reg_write_byte(bus,0x57,0x08,0) &&
       !i2c_reg_write_byte(bus,0x57,0x0a,0x23) && /* 4096 nA / 50 Hz / 411us */
       !i2c_reg_write_byte(bus,0x57,0x0c,0x1f) && !i2c_reg_write_byte(bus,0x57,0x0d,0x1f) &&
       !i2c_reg_write_byte(bus,0x57,0x09,0x03);
   }
 }
 if(IS_ENABLED(CONFIG_SENSEMIND_BRINGUP_LOG))
   printk("SM MAX30102 part_id rc=%d id=0x%02x ready=%d\n",rc_ppg_id,id,ppg_ok);
 return (imu_ok||ppg_ok)?0:-ENODEV;
}
void sm_bringup_scan(void) {
 if(!bus)bus=DEVICE_DT_GET(DT_NODELABEL(i2c1));
 if(!device_is_ready(bus)){printk("SM I2C not ready\n");return;}
 printk("SM I2C scan:");
 for(uint8_t a=0x08;a<0x78;a++){uint8_t v;if(!i2c_reg_read_byte(bus,a,0x00,&v))printk(" 0x%02x",a);}
 uint8_t id=0;int rc=i2c_reg_read_byte(bus,0x68,0x75,&id);
 printk("\nSM MPU who_am_i rc=%d id=0x%02x",rc,id);
 id=0;rc=i2c_reg_read_byte(bus,0x57,0xff,&id);
 printk(" | MAX part_id rc=%d id=0x%02x\n",rc,id);
}
int sm_mpu6050_read(int16_t values[6]) {
 if(!imu_ok)return -ENODEV;
 uint8_t b[14];int rc=i2c_burst_read(bus,0x68,0x3b,b,sizeof(b));
 if(rc)return rc;
 values[0]=(int16_t)sys_get_be16(b);values[1]=(int16_t)sys_get_be16(b+2);values[2]=(int16_t)sys_get_be16(b+4);
 values[3]=(int16_t)sys_get_be16(b+8);values[4]=(int16_t)sys_get_be16(b+10);values[5]=(int16_t)sys_get_be16(b+12);return 0;
}
int sm_max30102_read(uint32_t *red,uint32_t *ir) {
 if(!ppg_ok)return -ENODEV;
 uint8_t wr,rd,overflow,b[6];
 if(i2c_reg_read_byte(bus,0x57,0x04,&wr)||i2c_reg_read_byte(bus,0x57,0x06,&rd)||i2c_reg_read_byte(bus,0x57,0x05,&overflow))return -EIO;
 if(overflow) { i2c_reg_write_byte(bus,0x57,0x05,0);i2c_reg_write_byte(bus,0x57,0x06,wr&31);return -EOVERFLOW; }
 if((wr&31)==(rd&31))return -EAGAIN;
 if(i2c_burst_read(bus,0x57,0x07,b,6))return -EIO;
 *red=(((uint32_t)b[0]<<16)|((uint32_t)b[1]<<8)|b[2])&0x3ffff;
 *ir=(((uint32_t)b[3]<<16)|((uint32_t)b[4]<<8)|b[5])&0x3ffff;return 0;
}
int sm_st7789v_init(void) { return -ENOTSUP; }
```

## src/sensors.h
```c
#ifndef SENSEMIND_SENSORS_H
#define SENSEMIND_SENSORS_H
#include <stdbool.h>
#include <stdint.h>
int sm_sensors_init(void);
bool sm_imu_present(void);
bool sm_ppg_present(void);
void sm_bringup_scan(void);
int sm_mpu6050_read(int16_t values[6]);
int sm_max30102_read(uint32_t *red, uint32_t *ir);
int sm_st7789v_init(void); /* Intentionally unsupported: SPI/display disabled. */
#endif
```

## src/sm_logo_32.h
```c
/* SenseMind app logo, rendered from res/drawable/ic_launcher.xml at 32x32.
 * RGB565, big-endian. The launcher background (#081020) is keyed to the
 * product background (#080D16) so the mark sits directly on the dark UI. */
#ifndef SM_LOGO_32_H
#define SM_LOGO_32_H
#include <stdint.h>
static const uint16_t sm_logo_32[1024] = {
    0x6208, 0x6208, 0x6208, 0x6208, 0x6208, 0x6208, 0x6208, 0x6208, 0x6208, 0x6208, 0x6208, 0x6208, 0x6208, 0x6208, 0x6208, 0x6208,
    0x6208, 0x6208, 0x6208, 0x6208, 0x6208, 0x6208, 0x6208, 0x6208, 0x6208, 0x6208, 0x6208, 0x6208, 0x6208, 0x6208, 0x6208, 0x6208,
    0x6208, 0x6208, 0x6208, 0x6208, 0x6208, 0x6208, 0x6208, 0x6208, 0x6208, 0x6208, 0x6208, 0x6208, 0x6208, 0x6208, 0x6208, 0x6208,
    0x6208, 0x6208, 0x6208, 0x6208, 0x6208, 0x6208, 0x6208, 0x6208, 0x6208, 0x6208, 0x6208, 0x6208, 0x6208, 0x6208, 0x6208, 0x6208,
    0x6208, 0x6208, 0x6208, 0x6208, 0x6208, 0x6208, 0x6208, 0x6208, 0x6208, 0x6208, 0x6208, 0x6208, 0x6208, 0x6208, 0x6208, 0x6208,
    0x6208, 0x6208, 0x6208, 0x6208, 0x6208, 0x6208, 0x6208, 0x6208, 0x6208, 0x6208, 0x6208, 0x6208, 0x6208, 0x6208, 0x6208, 0x6208,
    0x6208, 0x6208, 0x6208, 0x6208, 0x6208, 0x6208, 0x6208, 0x6208, 0x6208, 0x6208, 0x6208, 0x6208, 0x6208, 0x6208, 0x6208, 0x6208,
    0x6208, 0x6208, 0x6208, 0x6208, 0x6208, 0x6208, 0x6208, 0x6208, 0x6208, 0x6208, 0x6208, 0x6208, 0x6208, 0x6208, 0x6208, 0x6208,
    0x6208, 0x6208, 0x6208, 0x6208, 0x6208, 0x6208, 0x6208, 0x6208, 0x6208, 0x6208, 0x6208, 0x6208, 0x6208, 0x6208, 0x6208, 0x6208,
    0x6208, 0x6208, 0x6208, 0x6208, 0x6208, 0x6208, 0x6208, 0x6208, 0x6208, 0x6208, 0x6208, 0x6208, 0x6208, 0x6208, 0x6208, 0x6208,
    0x6208, 0x6208, 0x6208, 0x6208, 0x6208, 0x6208, 0x6208, 0x6208, 0x6208, 0x6208, 0x6208, 0x6208, 0xdb67, 0xdc67, 0xbb67, 0x9b67,
    0x9b67, 0xbb67, 0xdc67, 0xdb67, 0x6208, 0x6208, 0x6208, 0x6208, 0x6208, 0x6208, 0x6208, 0x6208, 0x6208, 0x6208, 0x6208, 0x6208,
    0x6208, 0x6208, 0x6208, 0x6208, 0x6208, 0x6208, 0x6208, 0x6208, 0x6208, 0x6208, 0xfc67, 0x7a67, 0x3a5f, 0x3a5f, 0x5a5f, 0x5a5f,
    0x5a5f, 0x5a5f, 0x3a5f, 0x3a5f, 0x7a67, 0xfc67, 0x6208, 0x6208, 0x6208, 0x6208, 0x6208, 0x6208, 0x6208, 0x6208, 0x6208, 0x6208,
    0x6208, 0x6208, 0x6208, 0x6208, 0x6208, 0x6208, 0x6208, 0x6208, 0x7a5f, 0x9b67, 0x3a5f, 0x5a5f, 0x5a5f, 0x5a5f, 0x5a5f, 0x5a5f,
    0x5a5f, 0x5a5f, 0x5a5f, 0x5a5f, 0x5a5f, 0x3a5f, 0x9b67, 0x7a5f, 0x6208, 0x6208, 0x6208, 0x6208, 0x6208, 0x6208, 0x6208, 0x6208,
    0x6208, 0x6208, 0x6208, 0x6208, 0x6208, 0x6208, 0x6208, 0x7a5f, 0x7a5f, 0x3a5f, 0x5a5f, 0x5a5f, 0x5a5f, 0x5a5f, 0x5a5f, 0x5a5f,
    0x5a5f, 0x5a5f, 0x5a5f, 0x5a5f, 0x5a5f, 0x5a5f, 0x3a5f, 0x7a5f, 0x7a5f, 0x6208, 0x6208, 0x6208, 0x6208, 0x6208, 0x6208, 0x6208,
    0x6208, 0x6208, 0x6208, 0x6208, 0x6208, 0x6208, 0x6208, 0x9b67, 0x3a5f, 0x5a5f, 0x5a5f, 0x5a5f, 0x5a5f, 0x5a5f, 0x5a5f, 0x5a5f,
    0x5a5f, 0x5a5f, 0x5a5f, 0x5a5f, 0x5a5f, 0x5a5f, 0x5a5f, 0x3a5f, 0x9b67, 0x6208, 0x6208, 0x6208, 0x6208, 0x6208, 0x6208, 0x6208,
    0x6208, 0x6208, 0x6208, 0x6208, 0x6208, 0x6208, 0xfc67, 0x3a5f, 0x5a5f, 0x5a5f, 0x5a5f, 0x5a5f, 0x5a5f, 0x5a5f, 0x5a5f, 0x5a5f,
    0x5a5f, 0x5a5f, 0x5a5f, 0x5a5f, 0x5a5f, 0x5a5f, 0x5a5f, 0x5a5f, 0x3a5f, 0xfc67, 0x6208, 0x6208, 0x6208, 0x6208, 0x6208, 0x6208,
    0x6208, 0x6208, 0x6208, 0x6208, 0x6208, 0x6208, 0x7a5f, 0x5a5f, 0x5a5f, 0x5a5f, 0x5a5f, 0x5a5f, 0x3a5f, 0x5a5f, 0x5a5f, 0x5a5f,
    0x5a5f, 0x5a5f, 0x5a5f, 0x5a5f, 0x5a5f, 0x5a5f, 0x5a5f, 0x5a5f, 0x5a5f, 0x7a5f, 0x6208, 0x6208, 0x6208, 0x6208, 0x6208, 0x6208,
    0x6208, 0x6208, 0x6208, 0x6208, 0x6208, 0xdc67, 0x3a5f, 0x5a5f, 0x5a5f, 0x5a5f, 0x7a67, 0xf95e, 0x0f34, 0x7b67, 0x5a5f, 0x5a5f,
    0x5a5f, 0x5a5f, 0x5a5f, 0x5a5f, 0x5a5f, 0x5a5f, 0x5a5f, 0x5a5f, 0x5a5f, 0x3a5f, 0xdc67, 0x6208, 0x6208, 0x6208, 0x6208, 0x6208,
    0x6208, 0x6208, 0x6208, 0x6208, 0x6208, 0xdc67, 0x3a5f, 0x5a5f, 0x5a5f, 0x3a5f, 0xbc67, 0x5345, 0x0409, 0x5a5f, 0x7a5f, 0x5a5f,
    0x7a5f, 0x9b67, 0x5a5f, 0x5a5f, 0x5a5f, 0x5a5f, 0x5a5f, 0x5a5f, 0x5a5f, 0x3a5f, 0xdc67, 0x6208, 0x6208, 0x6208, 0x6208, 0x6208,
    0x6208, 0x6208, 0x6208, 0x6208, 0x6208, 0xbb67, 0x3a5f, 0x3a5f, 0x3a5f, 0x195f, 0xbc67, 0x2c2b, 0x0100, 0x3656, 0x9b67, 0x7a67,
    0x9756, 0xd23c, 0xbb67, 0x395f, 0x3a5f, 0x3a5f, 0x3a5f, 0x3a5f, 0x3a5f, 0x3a5f, 0xbb67, 0x6208, 0x6208, 0x6208, 0x6208, 0x6208,
    0x6208, 0x6208, 0x6208, 0x6208, 0x6208, 0x9b67, 0x5a5f, 0xdc67, 0xdc67, 0xfc67, 0x3a5f, 0x0509, 0x0000, 0x913c, 0xbb67, 0xbb67,
    0x1245, 0x6200, 0xb856, 0xfd6f, 0xdc67, 0xdc67, 0xdc67, 0xdc67, 0xdc67, 0x5a5f, 0x9b67, 0x6208, 0x6208, 0x6208, 0x6208, 0x6208,
    0x6208, 0x6208, 0x6208, 0x6208, 0x6208, 0x9b67, 0x195f, 0x4f34, 0xee33, 0x2f34, 0x0b23, 0x6200, 0xa308, 0xcb22, 0xbb67, 0xbb67,
    0x0b23, 0x0000, 0x281a, 0x5034, 0xee33, 0x0f34, 0x0f34, 0xee33, 0x4f34, 0x195f, 0x9b67, 0x6208, 0x6208, 0x6208, 0x6208, 0x6208,
    0x6208, 0x6208, 0x6208, 0x6208, 0x6208, 0xdc67, 0xb856, 0x0100, 0x0000, 0x0000, 0x0000, 0x6611, 0x913c, 0x0509, 0x5a5f, 0xf95e,
    0x0409, 0x4200, 0x0000, 0x0000, 0x0000, 0x0000, 0x0000, 0x0000, 0x0100, 0xb856, 0xdc67, 0x6208, 0x6208, 0x6208, 0x6208, 0x6208,
    0x6208, 0x6208, 0x6208, 0x6208, 0x6208, 0xdc67, 0x195f, 0x1245, 0xd13c, 0xf23c, 0xb13c, 0xd54d, 0xd856, 0x8300, 0x7756, 0x9445,
    0x0000, 0x903c, 0x1245, 0xd13c, 0xf23c, 0xf23c, 0xf23c, 0xd13c, 0x1245, 0x195f, 0xdc67, 0x6208, 0x6208, 0x6208, 0x6208, 0x6208,
    0x6208, 0x6208, 0x6208, 0x6208, 0x6208, 0xbb67, 0x5a5f, 0xdc67, 0xdc67, 0xdc67, 0xdc67, 0x9b67, 0x9b67, 0x4511, 0xd13c, 0x4c2b,
    0xa308, 0x7a5f, 0xfc67, 0xdc67, 0xdc67, 0xdc67, 0xdc67, 0xdc67, 0xdc67, 0x5a5f, 0xbb67, 0x6208, 0x6208, 0x6208, 0x6208, 0x6208,
    0x6208, 0x6208, 0x6208, 0x6208, 0x6208, 0x6208, 0x7a5f, 0x3a5f, 0x3a5f, 0x3a5f, 0x3a5f, 0x395f, 0xfc67, 0x2c2b, 0x081a, 0x0509,
    0x0b23, 0xdc67, 0x195f, 0x3a5f, 0x3a5f, 0x3a5f, 0x3a5f, 0x3a5f, 0x3a5f, 0x7a5f, 0x6208, 0x6208, 0x6208, 0x6208, 0x6208, 0x6208,
    0x6208, 0x6208, 0x6208, 0x6208, 0x6208, 0x6208, 0xfc67, 0x3a5f, 0x5a5f, 0x5a5f, 0x5a5f, 0x3a5f, 0xdc67, 0x3345, 0x2100, 0x4200,
    0x7445, 0xbb67, 0x3a5f, 0x5a5f, 0x5a5f, 0x5a5f, 0x5a5f, 0x5a5f, 0x3a5f, 0xfc67, 0x6208, 0x6208, 0x6208, 0x6208, 0x6208, 0x6208,
    0x6208, 0x6208, 0x6208, 0x6208, 0x6208, 0x6208, 0x6208, 0x9b67, 0x3a5f, 0x5a5f, 0x5a5f, 0x5a5f, 0x9b67, 0x9856, 0x8308, 0x0409,
    0xf95e, 0x7a5f, 0x5a5f, 0x5a5f, 0x5a5f, 0x5a5f, 0x5a5f, 0x3a5f, 0x9b67, 0x6208, 0x6208, 0x6208, 0x6208, 0x6208, 0x6208, 0x6208,
    0x6208, 0x6208, 0x6208, 0x6208, 0x6208, 0x6208, 0x6208, 0x7a5f, 0x7a5f, 0x3a5f, 0x5a5f, 0x5a5f, 0x5a5f, 0x9b67, 0x6611, 0xaa22,
    0xdc67, 0x3a5f, 0x5a5f, 0x5a5f, 0x5a5f, 0x5a5f, 0x3a5f, 0x7a5f, 0x7a5f, 0x6208, 0x6208, 0x6208, 0x6208, 0x6208, 0x6208, 0x6208,
    0x6208, 0x6208, 0x6208, 0x6208, 0x6208, 0x6208, 0x6208, 0x6208, 0x7a5f, 0x9b67, 0x3a5f, 0x5a5f, 0x3a5f, 0xfc67, 0x0b2b, 0xb13c,
    0xdc67, 0x3a5f, 0x5a5f, 0x5a5f, 0x5a5f, 0x3a5f, 0x9b67, 0x7a5f, 0x6208, 0x6208, 0x6208, 0x6208, 0x6208, 0x6208, 0x6208, 0x6208,
    0x6208, 0x6208, 0x6208, 0x6208, 0x6208, 0x6208, 0x6208, 0x6208, 0x6208, 0x6208, 0xfc67, 0x7a67, 0x3a5f, 0x7b67, 0xd54d, 0x9756,
    0x7a5f, 0x3a5f, 0x3a5f, 0x3a5f, 0x7a67, 0xfc67, 0x6208, 0x6208, 0x6208, 0x6208, 0x6208, 0x6208, 0x6208, 0x6208, 0x6208, 0x6208,
    0x6208, 0x6208, 0x6208, 0x6208, 0x6208, 0x6208, 0x6208, 0x6208, 0x6208, 0x6208, 0x6208, 0x6208, 0xdc67, 0xdc67, 0xdc67, 0x9b67,
    0x9b67, 0xbb67, 0xdc67, 0xdb67, 0x6208, 0x6208, 0x6208, 0x6208, 0x6208, 0x6208, 0x6208, 0x6208, 0x6208, 0x6208, 0x6208, 0x6208,
    0x6208, 0x6208, 0x6208, 0x6208, 0x6208, 0x6208, 0x6208, 0x6208, 0x6208, 0x6208, 0x6208, 0x6208, 0x6208, 0x6208, 0x6208, 0x6208,
    0x6208, 0x6208, 0x6208, 0x6208, 0x6208, 0x6208, 0x6208, 0x6208, 0x6208, 0x6208, 0x6208, 0x6208, 0x6208, 0x6208, 0x6208, 0x6208,
    0x6208, 0x6208, 0x6208, 0x6208, 0x6208, 0x6208, 0x6208, 0x6208, 0x6208, 0x6208, 0x6208, 0x6208, 0x6208, 0x6208, 0x6208, 0x6208,
    0x6208, 0x6208, 0x6208, 0x6208, 0x6208, 0x6208, 0x6208, 0x6208, 0x6208, 0x6208, 0x6208, 0x6208, 0x6208, 0x6208, 0x6208, 0x6208,
    0x6208, 0x6208, 0x6208, 0x6208, 0x6208, 0x6208, 0x6208, 0x6208, 0x6208, 0x6208, 0x6208, 0x6208, 0x6208, 0x6208, 0x6208, 0x6208,
    0x6208, 0x6208, 0x6208, 0x6208, 0x6208, 0x6208, 0x6208, 0x6208, 0x6208, 0x6208, 0x6208, 0x6208, 0x6208, 0x6208, 0x6208, 0x6208,
    0x6208, 0x6208, 0x6208, 0x6208, 0x6208, 0x6208, 0x6208, 0x6208, 0x6208, 0x6208, 0x6208, 0x6208, 0x6208, 0x6208, 0x6208, 0x6208,
    0x6208, 0x6208, 0x6208, 0x6208, 0x6208, 0x6208, 0x6208, 0x6208, 0x6208, 0x6208, 0x6208, 0x6208, 0x6208, 0x6208, 0x6208, 0x6208,
    0x6208, 0x6208, 0x6208, 0x6208, 0x6208, 0x6208, 0x6208, 0x6208, 0x6208, 0x6208, 0x6208, 0x6208, 0x6208, 0x6208, 0x6208, 0x6208,
    0x6208, 0x6208, 0x6208, 0x6208, 0x6208, 0x6208, 0x6208, 0x6208, 0x6208, 0x6208, 0x6208, 0x6208, 0x6208, 0x6208, 0x6208, 0x6208,
};
#endif /* SM_LOGO_32_H */
```
